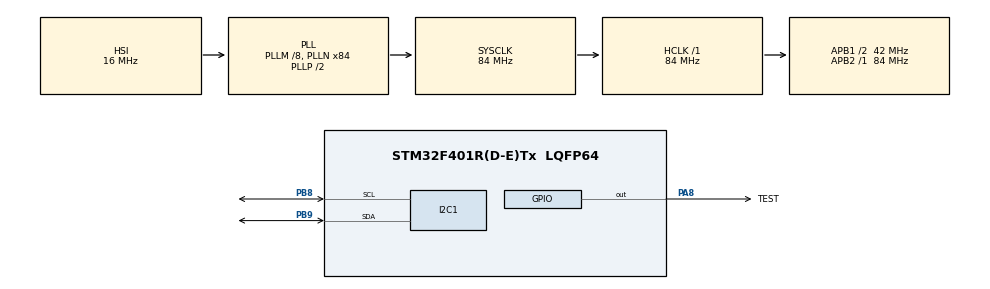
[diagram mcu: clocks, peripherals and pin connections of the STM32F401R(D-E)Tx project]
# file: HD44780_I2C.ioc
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Mcu.Family=STM32F4
Mcu.Name=STM32F401R(D-E)Tx
Mcu.Package=LQFP64
NVIC.PriorityGroup=NVIC_PRIORITYGROUP_4
PA8.GPIO_Label=TEST
PA8.Signal=GPIO_Output
PB8.Mode=I2C
PB8.Signal=I2C1_SCL
PB9.Mode=I2C
PB9.Signal=I2C1_SDA
ProjectManager.HeapSize=0x200
ProjectManager.StackSize=0x400
ProjectManager.TargetToolchain=STM32CubeIDE
RCC.48MHZClocksFreq_Value=42000000
RCC.AHBFreq_Value=84000000
RCC.APB1CLKDivider=RCC_HCLK_DIV2
RCC.APB1Freq_Value=42000000
RCC.APB1TimFreq_Value=84000000
RCC.APB2Freq_Value=84000000
RCC.APB2TimFreq_Value=84000000
RCC.CortexFreq_Value=84000000
RCC.HCLKFreq_Value=84000000
RCC.HSE_VALUE=25000000
RCC.HSI_VALUE=16000000
RCC.LSE_VALUE=32768
RCC.PLLM=8
RCC.PLLN=84
RCC.SYSCLKFreq_VALUE=84000000
RCC.SYSCLKSource=RCC_SYSCLKSOURCE_PLLCLK
RCC.VCOOutputFreq_Value=168000000
TIM3.Period=0xFFFF
TIM3.Prescaler=83
VP_TIM3_VS_ClockSourceINT.Mode=Internal
board=custom

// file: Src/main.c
/* USER CODE BEGIN Header */
/**
  ******************************************************************************
  * @file           : main.c
  * @brief          : Main program body
  ******************************************************************************
  * @attention
  *
  * <h2><center>&copy; Copyright (c) 2019 STMicroelectronics.
  * All rights reserved.</center></h2>
  *
  * This software component is licensed by ST under BSD 3-Clause license,
  * the "License"; You may not use this file except in compliance with the
  * License. You may obtain a copy of the License at:
  *                        opensource.org/licenses/BSD-3-Clause
  *
  ******************************************************************************
  *  Created on: 23.06.2019
  *      Author: Mateusz Salamon
  *		 mateusz@msalamon.pl
  *
  *      Website: https://msalamon.pl/czy-konwerter-i2c-z-lcd-to-dobrana-para/
  *      GitHub:  https://github.com/lamik/LCD_I2C_STM32_HAL
  */
/* USER CODE END Header */

#include "main.h"
#include "i2c.h"
#include "tim.h"
#include "gpio.h"

/* USER CODE BEGIN Includes */
#include "LCD_HD44780_I2C.h"
/* USER CODE END Includes */

void SystemClock_Config(void);

int main(void)
{

  /* MCU Configuration--------------------------------------------------------*/

  /* Reset of all peripherals, Initializes the Flash interface and the Systick. */
  HAL_Init();

  /* Configure the system clock */
  SystemClock_Config();

  /* Initialize all configured peripherals */
  MX_GPIO_Init();
  MX_I2C1_Init();
  MX_TIM3_Init();
  /* USER CODE BEGIN 2 */
  HAL_TIM_Base_Start(&htim3);
  LCD_Init(&hi2c1);
  /* USER CODE END 2 */

  /* Infinite loop */
  /* USER CODE BEGIN WHILE */
  while (1)
  {
	  HAL_GPIO_WritePin(TEST_GPIO_Port, TEST_Pin, 1);
	  // Measurement start
	  LCD_Cls();
	  LCD_Locate(0,0);
	  LCD_String(" STM32 + HD44780");
	  LCD_Locate(0,1);
	  LCD_String("www.msalamon.pl ");
	  // Measurement end
	  HAL_GPIO_WritePin(TEST_GPIO_Port, TEST_Pin, 0);
	  HAL_Delay(500);
    /* USER CODE END WHILE */

  }
}

void SystemClock_Config(void)
{
  RCC_OscInitTypeDef RCC_OscInitStruct = {0};
  RCC_ClkInitTypeDef RCC_ClkInitStruct = {0};

  /** Configure the main internal regulator output voltage
  */
  __HAL_RCC_PWR_CLK_ENABLE();
  __HAL_PWR_VOLTAGESCALING_CONFIG(PWR_REGULATOR_VOLTAGE_SCALE2);
  /** Initializes the CPU, AHB and APB busses clocks
  */
  RCC_OscInitStruct.OscillatorType = RCC_OSCILLATORTYPE_HSI;
  RCC_OscInitStruct.HSIState = RCC_HSI_ON;
  RCC_OscInitStruct.HSICalibrationValue = RCC_HSICALIBRATION_DEFAULT;
  RCC_OscInitStruct.PLL.PLLState = RCC_PLL_ON;
  RCC_OscInitStruct.PLL.PLLSource = RCC_PLLSOURCE_HSI;
  RCC_OscInitStruct.PLL.PLLM = 8;
  RCC_OscInitStruct.PLL.PLLN = 84;
  RCC_OscInitStruct.PLL.PLLP = RCC_PLLP_DIV2;
  RCC_OscInitStruct.PLL.PLLQ = 4;
  if (HAL_RCC_OscConfig(&RCC_OscInitStruct) != HAL_OK)
  {
    Error_Handler();
  }
  /** Initializes the CPU, AHB and APB busses clocks
  */
  RCC_ClkInitStruct.ClockType = RCC_CLOCKTYPE_HCLK|RCC_CLOCKTYPE_SYSCLK
                              |RCC_CLOCKTYPE_PCLK1|RCC_CLOCKTYPE_PCLK2;
  RCC_ClkInitStruct.SYSCLKSource = RCC_SYSCLKSOURCE_PLLCLK;
  RCC_ClkInitStruct.AHBCLKDivider = RCC_SYSCLK_DIV1;
  RCC_ClkInitStruct.APB1CLKDivider = RCC_HCLK_DIV2;
  RCC_ClkInitStruct.APB2CLKDivider = RCC_HCLK_DIV1;

  if (HAL_RCC_ClockConfig(&RCC_ClkInitStruct, FLASH_LATENCY_2) != HAL_OK)
  {
    Error_Handler();
  }
}

void Error_Handler(void)
{
}

/************************ (C) COPYRIGHT STMicroelectronics *****END OF FILE****/
